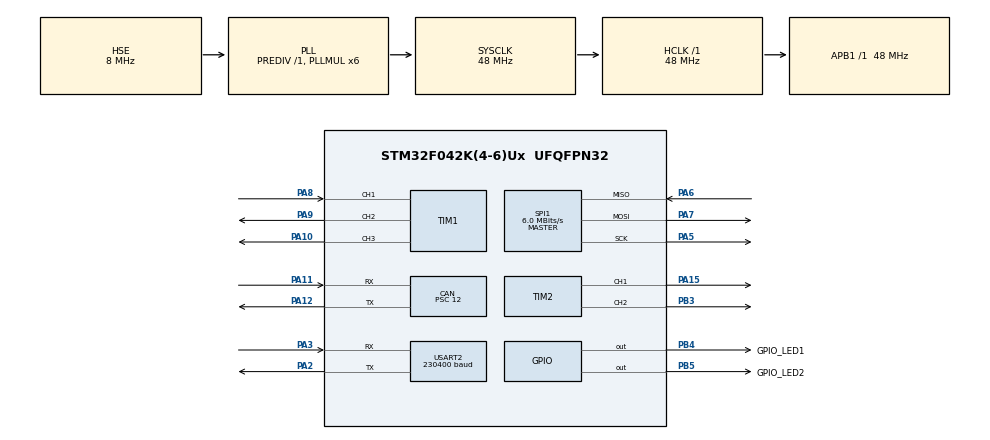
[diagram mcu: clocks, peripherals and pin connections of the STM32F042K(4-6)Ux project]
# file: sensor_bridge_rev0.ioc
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CAN.BS1=CAN_BS1_2TQ
CAN.BS2=CAN_BS2_2TQ
CAN.CalculateBaudRate=800000
CAN.CalculateTimeBit=1250
CAN.CalculateTimeQuantum=250.0
CAN.Prescaler=12
Dma.Request0=USART2_TX
Dma.USART2_TX.0.Direction=DMA_MEMORY_TO_PERIPH
Dma.USART2_TX.0.Instance=DMA1_Channel4
Dma.USART2_TX.0.MemDataAlignment=DMA_MDATAALIGN_BYTE
Dma.USART2_TX.0.MemInc=DMA_MINC_ENABLE
Dma.USART2_TX.0.Mode=DMA_NORMAL
Dma.USART2_TX.0.PeriphDataAlignment=DMA_PDATAALIGN_BYTE
Dma.USART2_TX.0.PeriphInc=DMA_PINC_DISABLE
Dma.USART2_TX.0.Priority=DMA_PRIORITY_LOW
Mcu.Family=STM32F0
Mcu.Name=STM32F042K(4-6)Ux
Mcu.Package=UFQFPN32
NVIC.CEC_CAN_IRQn=true\:0\:0\:false\:false\:true\:true\:true\:true
NVIC.DMA1_Channel4_5_IRQn=true\:0\:0\:false\:false\:true\:false\:true\:true
NVIC.USART2_IRQn=true\:0\:0\:false\:false\:true\:true\:true\:true
PA10.Signal=S_TIM1_CH3
PA11.Mode=CAN_Activate
PA11.Signal=CAN_RX
PA12.Mode=CAN_Activate
PA12.Signal=CAN_TX
PA15.Signal=S_TIM2_CH1_ETR
PA2.Mode=Asynchronous
PA2.Signal=USART2_TX
PA3.Mode=Asynchronous
PA3.Signal=USART2_RX
PA5.Mode=Full_Duplex_Master
PA5.Signal=SPI1_SCK
PA6.Mode=Full_Duplex_Master
PA6.Signal=SPI1_MISO
PA7.Mode=Full_Duplex_Master
PA7.Signal=SPI1_MOSI
PA8.Signal=S_TIM1_CH1
PA9.Signal=S_TIM1_CH2
PB3.Signal=S_TIM2_CH2
PB4.GPIO_Label=GPIO_LED1
PB4.Signal=GPIO_Output
PB5.GPIO_Label=GPIO_LED2
PB5.Signal=GPIO_Output
PF0-OSC_IN.Mode=HSE-External-Oscillator
PF0-OSC_IN.Signal=RCC_OSC_IN
PF1-OSC_OUT.Mode=HSE-External-Oscillator
PF1-OSC_OUT.Signal=RCC_OSC_OUT
ProjectManager.HeapSize=0x200
ProjectManager.StackSize=0x400
ProjectManager.TargetToolchain=STM32CubeIDE
RCC.AHBFreq_Value=48000000
RCC.APB1Freq_Value=48000000
RCC.APB1TimFreq_Value=48000000
RCC.HCLKFreq_Value=48000000
RCC.PLLMUL=RCC_PLL_MUL6
RCC.PLLSourceVirtual=RCC_PLLSOURCE_HSE
RCC.SYSCLKFreq_VALUE=48000000
RCC.SYSCLKSource=RCC_SYSCLKSOURCE_PLLCLK
SH.S_TIM1_CH1.0=TIM1_CH1,TriggerSource_TI1ED
SH.S_TIM1_CH2.0=TIM1_CH2,PWM Generation2 CH2
SH.S_TIM1_CH3.0=TIM1_CH3,PWM Generation3 CH3
SH.S_TIM2_CH1_ETR.0=TIM2_CH1,PWM Generation1 CH1
SH.S_TIM2_CH2.0=TIM2_CH2,PWM Generation2 CH2
SPI1.BaudRatePrescaler=SPI_BAUDRATEPRESCALER_8
SPI1.CalculateBaudRate=6.0 MBits/s
SPI1.DataSize=SPI_DATASIZE_8BIT
SPI1.Direction=SPI_DIRECTION_2LINES
SPI1.Mode=SPI_MODE_MASTER
SPI1.VirtualType=VM_MASTER
TIM1.Channel-Input_Capture1_from_TRC=TIM_CHANNEL_1
TIM1.Channel-PWM\ Generation2\ CH2=TIM_CHANNEL_2
TIM1.Channel-PWM\ Generation3\ CH3=TIM_CHANNEL_3
TIM2.Channel-PWM\ Generation1\ CH1=TIM_CHANNEL_1
TIM2.Channel-PWM\ Generation2\ CH2=TIM_CHANNEL_2
USART2.BaudRate=230400
USART2.VirtualMode-Asynchronous=VM_ASYNC
VP_TIM16_VS_ClockSourceINT.Mode=Enable_Timer
VP_TIM17_VS_ClockSourceINT.Mode=Enable_Timer
VP_TIM1_VS_CH1.Mode=Input_Capture1_from_TRC
board=custom

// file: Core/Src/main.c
/* USER CODE BEGIN Header */
/**
  ******************************************************************************
  * @file           : main.c
  * @brief          : Main program body
  ******************************************************************************
  * @attention
  *
  * Copyright (c) 2025 STMicroelectronics.
  * All rights reserved.
  *
  * This software is licensed under terms that can be found in the LICENSE file
  * in the root directory of this software component.
  * If no LICENSE file comes with this software, it is provided AS-IS.
  *
  ******************************************************************************
  */
/* USER CODE END Header */
#include "main.h"
#include "can.h"
#include "dma.h"
#include "spi.h"
#include "tim.h"
#include "usart.h"
#include "gpio.h"
#include "sensor_bridge.h"

/* USER CODE BEGIN Includes */
#include "sensor_bridge.h"
/* USER CODE END Includes */

void SystemClock_Config(void);

int main(void)
{

  /* MCU Configuration--------------------------------------------------------*/

  /* Reset of all peripherals, Initializes the Flash interface and the Systick. */
  HAL_Init();

  /* Configure the system clock */
  SystemClock_Config();

  /* Initialize all configured peripherals */
  MX_GPIO_Init();
  MX_DMA_Init();
  MX_CAN_Init();
  MX_TIM1_Init();
  MX_TIM2_Init();
  MX_TIM16_Init();
  MX_TIM17_Init();
  MX_USART2_UART_Init();
  MX_SPI1_Init();
  /* USER CODE BEGIN 2 */
  run_sensor_bridge();

  /* USER CODE END 2 */

  /* Infinite loop */
  while (1)
  {

  }
}

void SystemClock_Config(void)
{
  RCC_OscInitTypeDef RCC_OscInitStruct = {0};
  RCC_ClkInitTypeDef RCC_ClkInitStruct = {0};

  /** Initializes the RCC Oscillators according to the specified parameters
  * in the RCC_OscInitTypeDef structure.
  */
  RCC_OscInitStruct.OscillatorType = RCC_OSCILLATORTYPE_HSE;
  RCC_OscInitStruct.HSEState = RCC_HSE_ON;
  RCC_OscInitStruct.PLL.PLLState = RCC_PLL_ON;
  RCC_OscInitStruct.PLL.PLLSource = RCC_PLLSOURCE_HSE;
  RCC_OscInitStruct.PLL.PLLMUL = RCC_PLL_MUL6;
  RCC_OscInitStruct.PLL.PREDIV = RCC_PREDIV_DIV1;
  if (HAL_RCC_OscConfig(&RCC_OscInitStruct) != HAL_OK)
  {
    Error_Handler();
  }

  /** Initializes the CPU, AHB and APB buses clocks
  */
  RCC_ClkInitStruct.ClockType = RCC_CLOCKTYPE_HCLK|RCC_CLOCKTYPE_SYSCLK
                              |RCC_CLOCKTYPE_PCLK1;
  RCC_ClkInitStruct.SYSCLKSource = RCC_SYSCLKSOURCE_PLLCLK;
  RCC_ClkInitStruct.AHBCLKDivider = RCC_SYSCLK_DIV1;
  RCC_ClkInitStruct.APB1CLKDivider = RCC_HCLK_DIV1;

  if (HAL_RCC_ClockConfig(&RCC_ClkInitStruct, FLASH_LATENCY_1) != HAL_OK)
  {
    Error_Handler();
  }
}

void Error_Handler(void)
{
  __disable_irq();
  while (1)
  {
  }
}
